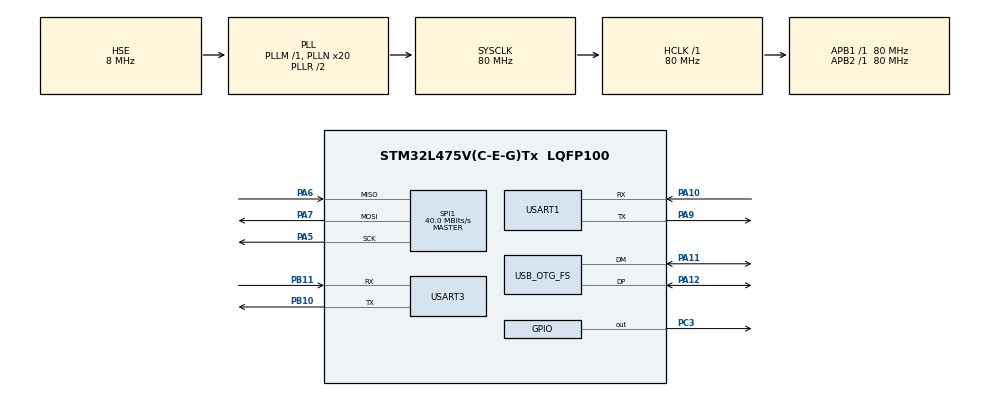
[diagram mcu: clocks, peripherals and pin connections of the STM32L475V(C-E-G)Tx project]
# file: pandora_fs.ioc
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Dma.Request0=USART3_RX
Dma.USART3_RX.0.Direction=DMA_PERIPH_TO_MEMORY
Dma.USART3_RX.0.Instance=DMA1_Channel3
Dma.USART3_RX.0.MemDataAlignment=DMA_MDATAALIGN_BYTE
Dma.USART3_RX.0.MemInc=DMA_MINC_ENABLE
Dma.USART3_RX.0.Mode=DMA_NORMAL
Dma.USART3_RX.0.PeriphDataAlignment=DMA_PDATAALIGN_BYTE
Dma.USART3_RX.0.PeriphInc=DMA_PINC_DISABLE
Dma.USART3_RX.0.Priority=DMA_PRIORITY_LOW
Mcu.Family=STM32L4
Mcu.Name=STM32L475V(C-E-G)Tx
Mcu.Package=LQFP100
NVIC.DMA1_Channel3_IRQn=true\:0\:0\:false\:false\:true\:false\:true
NVIC.OTG_FS_IRQn=true\:0\:0\:false\:false\:true\:true\:true
NVIC.PriorityGroup=NVIC_PRIORITYGROUP_4
PA10.Mode=Asynchronous
PA10.Signal=USART1_RX
PA11.Mode=Device_Only
PA11.Signal=USB_OTG_FS_DM
PA12.Mode=Device_Only
PA12.Signal=USB_OTG_FS_DP
PA13\ (JTMS-SWDIO).Mode=Serial_Wire
PA13\ (JTMS-SWDIO).Signal=SYS_JTMS-SWDIO
PA14\ (JTCK-SWCLK).Mode=Serial_Wire
PA14\ (JTCK-SWCLK).Signal=SYS_JTCK-SWCLK
PA5.Mode=Full_Duplex_Master
PA5.Signal=SPI1_SCK
PA6.Mode=Full_Duplex_Master
PA6.Signal=SPI1_MISO
PA7.Mode=Full_Duplex_Master
PA7.Signal=SPI1_MOSI
PA9.Mode=Asynchronous
PA9.Signal=USART1_TX
PB10.Mode=Asynchronous
PB10.Signal=USART3_TX
PB11.Mode=Asynchronous
PB11.Signal=USART3_RX
PC3.Signal=GPIO_Output
PH0-OSC_IN\ (PH0).Mode=HSE-External-Oscillator
PH0-OSC_IN\ (PH0).Signal=RCC_OSC_IN
PH1-OSC_OUT\ (PH1).Mode=HSE-External-Oscillator
PH1-OSC_OUT\ (PH1).Signal=RCC_OSC_OUT
ProjectManager.HeapSize=0x200
ProjectManager.StackSize=0x400
ProjectManager.TargetToolchain=EWARM V8
RCC.ADCFreq_Value=48000000
RCC.AHBFreq_Value=80000000
RCC.APB1Freq_Value=80000000
RCC.APB1TimFreq_Value=80000000
RCC.APB2Freq_Value=80000000
RCC.APB2TimFreq_Value=80000000
RCC.CortexFreq_Value=80000000
RCC.HCLKFreq_Value=80000000
RCC.HSE_VALUE=8000000
RCC.HSI_VALUE=16000000
RCC.LSE_VALUE=32768
RCC.MSI_VALUE=4000000
RCC.PLLN=20
RCC.PLLSAI1N=12
RCC.PLLSourceVirtual=RCC_PLLSOURCE_HSE
RCC.SYSCLKFreq_VALUE=80000000
RCC.SYSCLKSource=RCC_SYSCLKSOURCE_PLLCLK
RCC.USBFreq_Value=48000000
RCC.VCOOutputFreq_Value=160000000
SPI1.CalculateBaudRate=40.0 MBits/s
SPI1.Direction=SPI_DIRECTION_2LINES
SPI1.Mode=SPI_MODE_MASTER
SPI1.VirtualType=VM_MASTER
USART1.VirtualMode-Asynchronous=VM_ASYNC
USART3.VirtualMode-Asynchronous=VM_ASYNC
USB_OTG_FS.VirtualMode=Device_Only
board=custom

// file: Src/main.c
/* USER CODE BEGIN Header */
/**
  ******************************************************************************
  * @file           : main.c
  * @brief          : Main program body
  ******************************************************************************
  * @attention
  *
  * <h2><center>&copy; Copyright (c) 2019 STMicroelectronics.
  * All rights reserved.</center></h2>
  *
  * This software component is licensed by ST under BSD 3-Clause license,
  * the "License"; You may not use this file except in compliance with the
  * License. You may obtain a copy of the License at:
  *                        opensource.org/licenses/BSD-3-Clause
  *
  ******************************************************************************
  */
/* USER CODE END Header */

#include "main.h"

/* USER CODE BEGIN Includes */
#include <stdio.h>
/* USER CODE END Includes */

SPI_HandleTypeDef hspi1;

UART_HandleTypeDef huart1;
UART_HandleTypeDef huart3;
DMA_HandleTypeDef hdma_usart3_rx;

PCD_HandleTypeDef hpcd_USB_OTG_FS;

void SystemClock_Config(void);
static void MX_GPIO_Init(void);
static void MX_DMA_Init(void);
static void MX_USART3_UART_Init(void);
static void MX_SPI1_Init(void);
static void MX_USART1_UART_Init(void);
static void MX_USB_OTG_FS_PCD_Init(void);

/* USER CODE BEGIN 0 */
#ifdef __GNUC__
  /* With GCC/RAISONANCE, small printf (option LD Linker->Libraries->Small printf
     set to 'Yes') calls __io_putchar() */
  #define PUTCHAR_PROTOTYPE int __io_putchar(int ch)
#else
  #define PUTCHAR_PROTOTYPE int fputc(int ch, FILE *f)
#endif /* __GNUC__ */
/**
  * @brief  Retargets the C library printf function to the USART.
  * @param  None
  * @retval None
  */
PUTCHAR_PROTOTYPE
{
  /* Place your implementation of fputc here */
  /* e.g. write a character to the EVAL_COM1 and Loop until the end of transmission */
  HAL_UART_Transmit(&huart3, (uint8_t *)&ch, 1, 0xFFFF);

  return ch;
}
/* USER CODE END 0 */

int main(void)
{

  /* MCU Configuration--------------------------------------------------------*/

  /* Reset of all peripherals, Initializes the Flash interface and the Systick. */
  HAL_Init();

  /* Configure the system clock */
  SystemClock_Config();

  /* Initialize all configured peripherals */
  MX_GPIO_Init();
  MX_DMA_Init();
  MX_USART3_UART_Init();
  MX_SPI1_Init();
  MX_USART1_UART_Init();
  MX_USB_OTG_FS_PCD_Init();
  /* USER CODE BEGIN 2 */
  printf("\n\r UART Printf Example: retarget the C library printf function to the UART\n\r");
  /* USER CODE END 2 */

  /* Infinite loop */
  /* USER CODE BEGIN WHILE */
  while (1)
  {
    printf("\n\r welcome to www.waveshere.com !!!\n\r");
    HAL_Delay(1000);
    /* USER CODE END WHILE */

  }
}

void SystemClock_Config(void)
{
  RCC_OscInitTypeDef RCC_OscInitStruct = {0};
  RCC_ClkInitTypeDef RCC_ClkInitStruct = {0};
  RCC_PeriphCLKInitTypeDef PeriphClkInit = {0};

  /** Initializes the CPU, AHB and APB busses clocks
  */
  RCC_OscInitStruct.OscillatorType = RCC_OSCILLATORTYPE_HSE;
  RCC_OscInitStruct.HSEState = RCC_HSE_ON;
  RCC_OscInitStruct.PLL.PLLState = RCC_PLL_ON;
  RCC_OscInitStruct.PLL.PLLSource = RCC_PLLSOURCE_HSE;
  RCC_OscInitStruct.PLL.PLLM = 1;
  RCC_OscInitStruct.PLL.PLLN = 20;
  RCC_OscInitStruct.PLL.PLLP = RCC_PLLP_DIV7;
  RCC_OscInitStruct.PLL.PLLQ = RCC_PLLQ_DIV2;
  RCC_OscInitStruct.PLL.PLLR = RCC_PLLR_DIV2;
  if (HAL_RCC_OscConfig(&RCC_OscInitStruct) != HAL_OK)
  {
    Error_Handler();
  }
  /** Initializes the CPU, AHB and APB busses clocks
  */
  RCC_ClkInitStruct.ClockType = RCC_CLOCKTYPE_HCLK|RCC_CLOCKTYPE_SYSCLK
                              |RCC_CLOCKTYPE_PCLK1|RCC_CLOCKTYPE_PCLK2;
  RCC_ClkInitStruct.SYSCLKSource = RCC_SYSCLKSOURCE_PLLCLK;
  RCC_ClkInitStruct.AHBCLKDivider = RCC_SYSCLK_DIV1;
  RCC_ClkInitStruct.APB1CLKDivider = RCC_HCLK_DIV1;
  RCC_ClkInitStruct.APB2CLKDivider = RCC_HCLK_DIV1;

  if (HAL_RCC_ClockConfig(&RCC_ClkInitStruct, FLASH_LATENCY_4) != HAL_OK)
  {
    Error_Handler();
  }
  PeriphClkInit.PeriphClockSelection = RCC_PERIPHCLK_USART1|RCC_PERIPHCLK_USART3
                              |RCC_PERIPHCLK_USB;
  PeriphClkInit.Usart1ClockSelection = RCC_USART1CLKSOURCE_PCLK2;
  PeriphClkInit.Usart3ClockSelection = RCC_USART3CLKSOURCE_PCLK1;
  PeriphClkInit.UsbClockSelection = RCC_USBCLKSOURCE_PLLSAI1;
  PeriphClkInit.PLLSAI1.PLLSAI1Source = RCC_PLLSOURCE_HSE;
  PeriphClkInit.PLLSAI1.PLLSAI1M = 1;
  PeriphClkInit.PLLSAI1.PLLSAI1N = 12;
  PeriphClkInit.PLLSAI1.PLLSAI1P = RCC_PLLP_DIV7;
  PeriphClkInit.PLLSAI1.PLLSAI1Q = RCC_PLLQ_DIV2;
  PeriphClkInit.PLLSAI1.PLLSAI1R = RCC_PLLR_DIV2;
  PeriphClkInit.PLLSAI1.PLLSAI1ClockOut = RCC_PLLSAI1_48M2CLK;
  if (HAL_RCCEx_PeriphCLKConfig(&PeriphClkInit) != HAL_OK)
  {
    Error_Handler();
  }
  /** Configure the main internal regulator output voltage
  */
  if (HAL_PWREx_ControlVoltageScaling(PWR_REGULATOR_VOLTAGE_SCALE1) != HAL_OK)
  {
    Error_Handler();
  }
}

static void MX_SPI1_Init(void)
{

  /* SPI1 parameter configuration*/
  hspi1.Instance = SPI1;
  hspi1.Init.Mode = SPI_MODE_MASTER;
  hspi1.Init.Direction = SPI_DIRECTION_2LINES;
  hspi1.Init.DataSize = SPI_DATASIZE_4BIT;
  hspi1.Init.CLKPolarity = SPI_POLARITY_LOW;
  hspi1.Init.CLKPhase = SPI_PHASE_1EDGE;
  hspi1.Init.NSS = SPI_NSS_SOFT;
  hspi1.Init.BaudRatePrescaler = SPI_BAUDRATEPRESCALER_2;
  hspi1.Init.FirstBit = SPI_FIRSTBIT_MSB;
  hspi1.Init.TIMode = SPI_TIMODE_DISABLE;
  hspi1.Init.CRCCalculation = SPI_CRCCALCULATION_DISABLE;
  hspi1.Init.CRCPolynomial = 7;
  hspi1.Init.CRCLength = SPI_CRC_LENGTH_DATASIZE;
  hspi1.Init.NSSPMode = SPI_NSS_PULSE_ENABLE;
  if (HAL_SPI_Init(&hspi1) != HAL_OK)
  {
    Error_Handler();
  }

}

static void MX_USART1_UART_Init(void)
{

  huart1.Instance = USART1;
  huart1.Init.BaudRate = 115200;
  huart1.Init.WordLength = UART_WORDLENGTH_8B;
  huart1.Init.StopBits = UART_STOPBITS_1;
  huart1.Init.Parity = UART_PARITY_NONE;
  huart1.Init.Mode = UART_MODE_TX_RX;
  huart1.Init.HwFlowCtl = UART_HWCONTROL_NONE;
  huart1.Init.OverSampling = UART_OVERSAMPLING_16;
  huart1.Init.OneBitSampling = UART_ONE_BIT_SAMPLE_DISABLE;
  huart1.AdvancedInit.AdvFeatureInit = UART_ADVFEATURE_NO_INIT;
  if (HAL_UART_Init(&huart1) != HAL_OK)
  {
    Error_Handler();
  }

}

static void MX_USART3_UART_Init(void)
{

  huart3.Instance = USART3;
  huart3.Init.BaudRate = 115200;
  huart3.Init.WordLength = UART_WORDLENGTH_8B;
  huart3.Init.StopBits = UART_STOPBITS_1;
  huart3.Init.Parity = UART_PARITY_NONE;
  huart3.Init.Mode = UART_MODE_TX_RX;
  huart3.Init.HwFlowCtl = UART_HWCONTROL_NONE;
  huart3.Init.OverSampling = UART_OVERSAMPLING_16;
  huart3.Init.OneBitSampling = UART_ONE_BIT_SAMPLE_DISABLE;
  huart3.AdvancedInit.AdvFeatureInit = UART_ADVFEATURE_NO_INIT;
  if (HAL_UART_Init(&huart3) != HAL_OK)
  {
    Error_Handler();
  }

}

static void MX_USB_OTG_FS_PCD_Init(void)
{

  hpcd_USB_OTG_FS.Instance = USB_OTG_FS;
  hpcd_USB_OTG_FS.Init.dev_endpoints = 6;
  hpcd_USB_OTG_FS.Init.speed = PCD_SPEED_FULL;
  hpcd_USB_OTG_FS.Init.phy_itface = PCD_PHY_EMBEDDED;
  hpcd_USB_OTG_FS.Init.Sof_enable = DISABLE;
  hpcd_USB_OTG_FS.Init.low_power_enable = DISABLE;
  hpcd_USB_OTG_FS.Init.lpm_enable = DISABLE;
  hpcd_USB_OTG_FS.Init.battery_charging_enable = DISABLE;
  hpcd_USB_OTG_FS.Init.use_dedicated_ep1 = DISABLE;
  hpcd_USB_OTG_FS.Init.vbus_sensing_enable = DISABLE;
  if (HAL_PCD_Init(&hpcd_USB_OTG_FS) != HAL_OK)
  {
    Error_Handler();
  }

}

static void MX_DMA_Init(void)
{

  /* DMA controller clock enable */
  __HAL_RCC_DMA1_CLK_ENABLE();

  /* DMA interrupt init */
  /* DMA1_Channel3_IRQn interrupt configuration */
  HAL_NVIC_SetPriority(DMA1_Channel3_IRQn, 0, 0);
  HAL_NVIC_EnableIRQ(DMA1_Channel3_IRQn);

}

static void MX_GPIO_Init(void)
{
  GPIO_InitTypeDef GPIO_InitStruct = {0};

  /* GPIO Ports Clock Enable */
  __HAL_RCC_GPIOH_CLK_ENABLE();
  __HAL_RCC_GPIOC_CLK_ENABLE();
  __HAL_RCC_GPIOA_CLK_ENABLE();
  __HAL_RCC_GPIOB_CLK_ENABLE();

  /*Configure GPIO pin Output Level */
  HAL_GPIO_WritePin(GPIOC, GPIO_PIN_3, GPIO_PIN_RESET);

  /*Configure GPIO pin : PC3 */
  GPIO_InitStruct.Pin = GPIO_PIN_3;
  GPIO_InitStruct.Mode = GPIO_MODE_OUTPUT_PP;
  GPIO_InitStruct.Pull = GPIO_NOPULL;
  GPIO_InitStruct.Speed = GPIO_SPEED_FREQ_LOW;
  HAL_GPIO_Init(GPIOC, &GPIO_InitStruct);

}

void Error_Handler(void)
{
}

/************************ (C) COPYRIGHT STMicroelectronics *****END OF FILE****/
